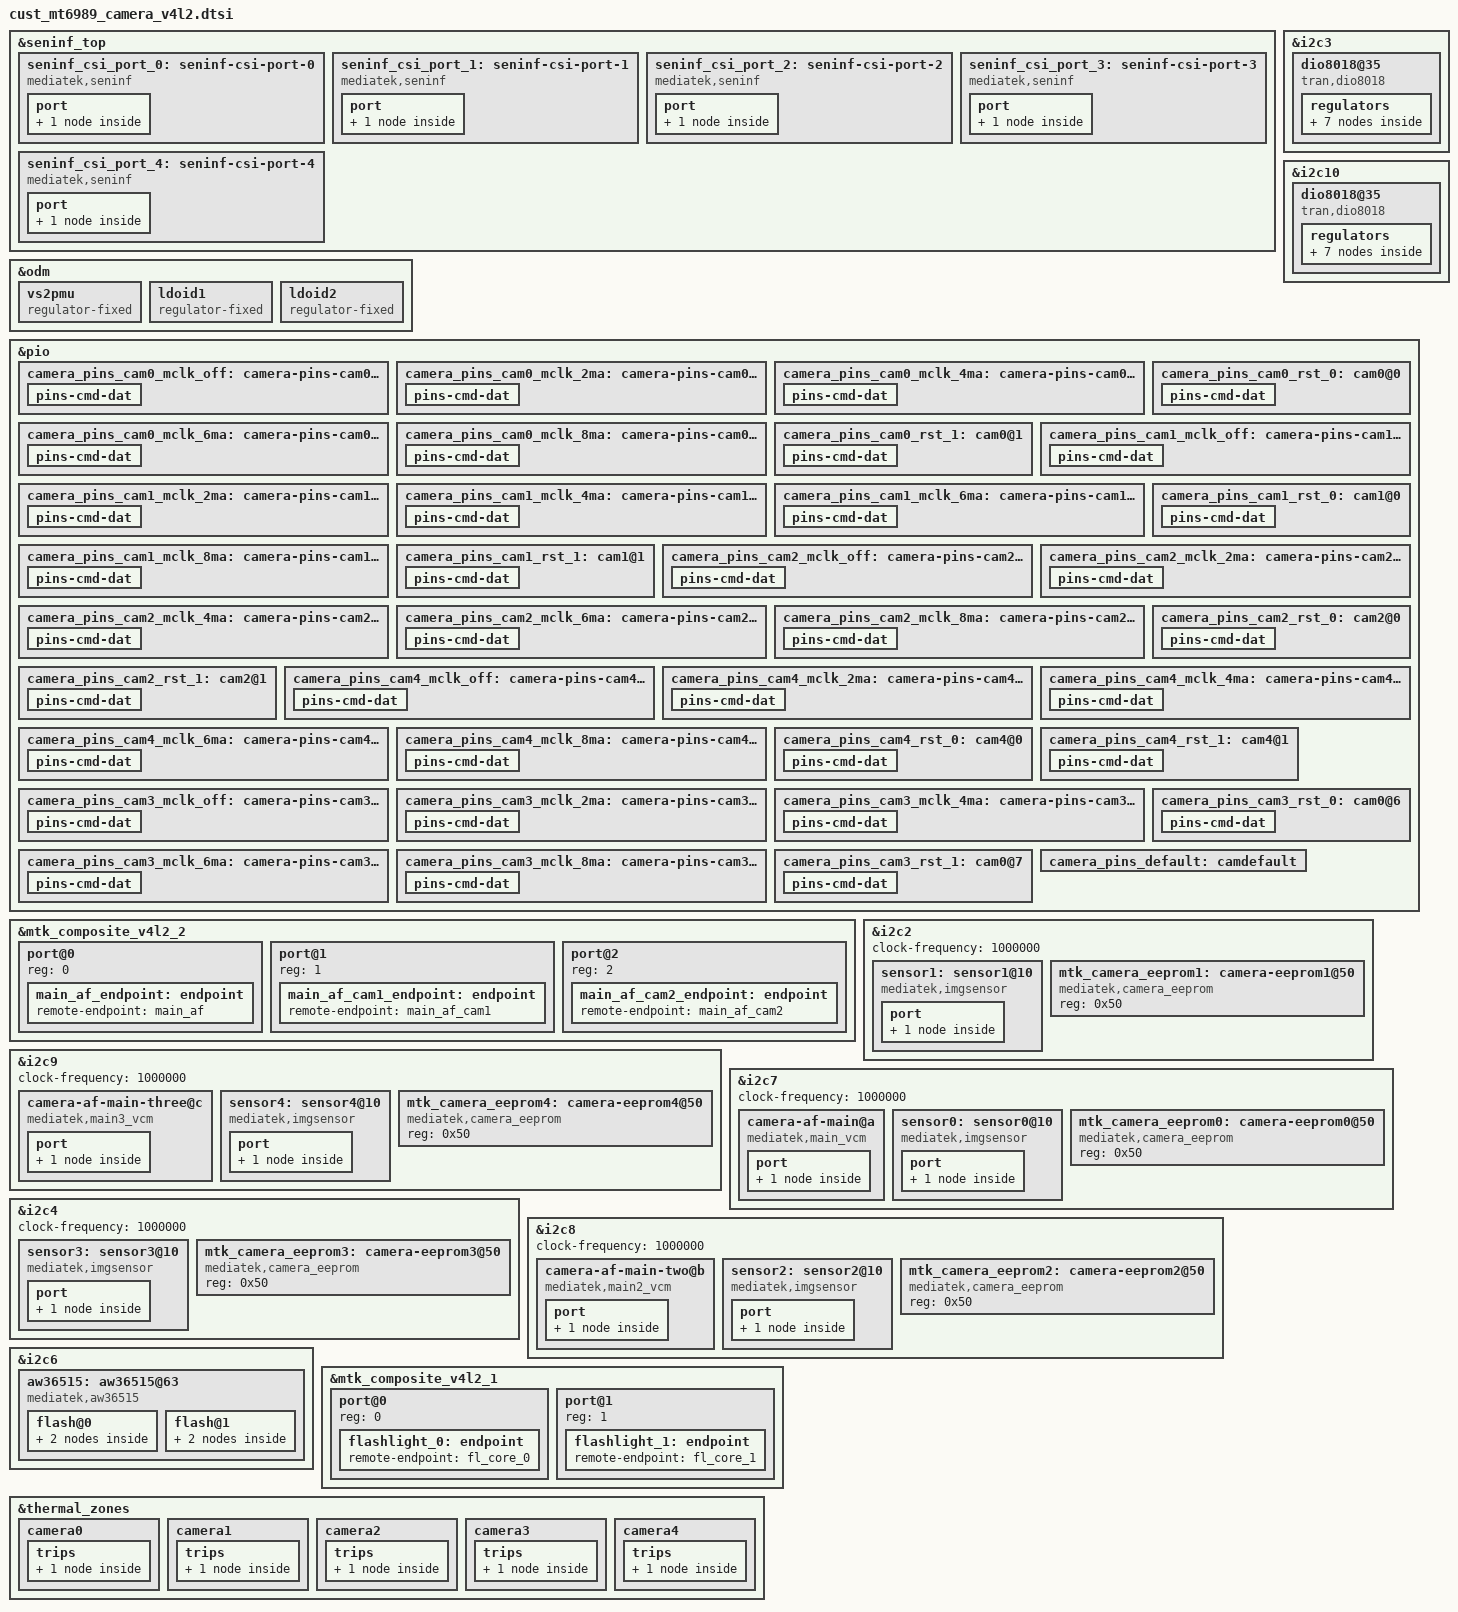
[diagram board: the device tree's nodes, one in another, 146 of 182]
// SPDX-License-Identifier: GPL-2.0
/* Copyright (c) 2023 MediaTek Inc. */
#include <dt-bindings/clock/mt6989-clk.h>

&seninf_top {
		seninf_csi_port_0: seninf-csi-port-0 {
			compatible = "mediatek,seninf";
			csi-port = "0";

			nvmem-cells = <&csi_efuse0>;
			nvmem-cell-names = "rg_csi";

			port {
				seninf_csi_port_0_in: endpoint {
					remote-endpoint = <&sensor4_out>;
				};
			};
		};

		seninf_csi_port_1: seninf-csi-port-1 {
			compatible = "mediatek,seninf";
			csi-port = "1";

			nvmem-cells = <&csi_efuse1>;
			nvmem-cell-names = "rg_csi";

			port {
				seninf_csi_port_1_in: endpoint {
					remote-endpoint = <&sensor2_out>;
				};
			};
		};

		seninf_csi_port_2: seninf-csi-port-2 {
			compatible = "mediatek,seninf";
			csi-port = "2";

			nvmem-cells = <&csi_efuse2>;
			nvmem-cell-names = "rg_csi";

			port {
				seninf_csi_port_2_in: endpoint {
					remote-endpoint = <&sensor1_out>;
				};
			};
		};
		seninf_csi_port_3: seninf-csi-port-3 {
			compatible = "mediatek,seninf";
			csi-port = "3";

			nvmem-cells = <&csi_efuse3>;
			nvmem-cell-names = "rg_csi";

			port {
				seninf_csi_port_3_in: endpoint {
					remote-endpoint = <&sensor0_out>;
				};
			};
		};
		seninf_csi_port_4: seninf-csi-port-4 {
			compatible = "mediatek,seninf";
			csi-port = "4";

			nvmem-cells = <&csi_efuse4>;
			nvmem-cell-names = "rg_csi";

			port {
				seninf_csi_port_4_in: endpoint {
					remote-endpoint = <&sensor3_out>;
				};
			};
		};
};

&i2c3 {
	#address-cells = <1>;
	#size-cells = <0>;

	dio8018@35 {
	    compatible = "tran,dio8018";
	    reg = <0x35>;
	    VINA-supply = <&vs2pmu>;
	    regulators {
	        DIO8018LDO13:DIO8018LDO13 {
	            regulator-name = "DIO8018LDO13";
	            regulator-min-microvolt = <800000>;
	            regulator-max-microvolt = <1800000>;
	        };
	        DIO8018LDO23:DIO8018LDO23 {
	            regulator-name = "DIO8018LDO23";
	            regulator-min-microvolt = <800000>;
	            regulator-max-microvolt = <1800000>;
	        };
	        DIO8018LDO33:DIO8018LDO33 {
	            regulator-name = "DIO8018LDO33";
	            regulator-min-microvolt = <1500000>;
	            regulator-max-microvolt = <3900000>;
	        };
	        DIO8018LDO43:DIO8018LDO43 {
	            regulator-name = "DIO8018LDO43";
	            regulator-min-microvolt = <1500000>;
	            regulator-max-microvolt = <3900000>;
	        };
	        DIO8018LDO53:DIO8018LDO53 {
	            regulator-name = "DIO8018LDO53";
	            regulator-min-microvolt = <3300000>;
	            regulator-max-microvolt = <3300000>;
	        };
	        DIO8018LDO63:DIO8018LDO63 {
	            regulator-name = "DIO8018LDO63";
	            regulator-min-microvolt = <1500000>;
	            regulator-max-microvolt = <3900000>;
	        };
	        DIO8018LDO73:DIO8018LDO73 {
	            regulator-name = "DIO8018LDO73";
	            regulator-min-microvolt = <1500000>;
	            regulator-max-microvolt = <3900000>;
	        };
	    };
	};
};

&i2c10 {
	#address-cells = <1>;
	#size-cells = <0>;

	dio8018@35 {
	    compatible = "tran,dio8018";
	    reg = <0x35>;
	    VINA-supply = <&vs2pmu>;
	    regulators {
	        DIO8018LDO110:DIO8018LDO110 {
	            regulator-name = "DIO8018LDO110";
	            regulator-min-microvolt = <800000>;
	            regulator-max-microvolt = <1800000>;
	        };
	        DIO8018LDO210:DIO8018LDO210 {
	            regulator-name = "DIO8018LDO210";
	            regulator-min-microvolt = <800000>;
	            regulator-max-microvolt = <1800000>;
	        };
	        DIO8018LDO310:DIO8018LDO310 {
	            regulator-name = "DIO8018LDO310";
	            regulator-min-microvolt = <1500000>;
	            regulator-max-microvolt = <3900000>;
	        };
	        DIO8018LDO410:DIO8018LDO410 {
	            regulator-name = "DIO8018LDO410";
	            regulator-min-microvolt = <1500000>;
	            regulator-max-microvolt = <3900000>;
	        };
	        DIO8018LDO510:DIO8018LDO510 {
	            regulator-name = "DIO8018LDO510";
	            regulator-min-microvolt = <3300000>;
	            regulator-max-microvolt = <3300000>;
	        };
	        DIO8018LDO610:DIO8018LDO610 {
	            regulator-name = "DIO8018LDO610";
	            regulator-min-microvolt = <2804000>;
	            regulator-max-microvolt = <2804000>;
	        };
	        DIO8018LDO710:DIO8018LDO710 {
	            regulator-name = "DIO8018LDO710";
	            regulator-min-microvolt = <1500000>;
	            regulator-max-microvolt = <3900000>;
	        };
	    };
	};
};

/* CAMERA GPIO fixed to regulator */
&odm {
	vs2pmu: vs2pmu {
		compatible = "regulator-fixed";
		regulator-name = "vs2pmu";
		regulator-min-microvolt = <1800000>;
		regulator-max-microvolt = <1800000>;
		gpio = <&pio 153 0x0>;
		enable-active-high;
		regulator-always-on;
		regulator-boot-on;
	};

	ldoid1: ldoid1 {
		compatible = "regulator-fixed";
		regulator-name = "ldoid1";
		regulator-min-microvolt = <1800000>;
		regulator-max-microvolt = <1800000>;
		gpio = <&pio 90 0x0>;
		enable-active-high;
		regulator-always-on;
		regulator-boot-on;
	};

	ldoid2: ldoid2 {
		compatible = "regulator-fixed";
		regulator-name = "ldoid2";
		regulator-min-microvolt = <1800000>;
		regulator-max-microvolt = <1800000>;
		gpio = <&pio 107 0x0>;
		enable-active-high;
		regulator-always-on;
		regulator-boot-on;
	};
};

/* CAMERA GPIO standardization */
&pio {
	camera_pins_cam0_mclk_off: camera-pins-cam0-mclk-off {
		pins-cmd-dat {
			pinmux = <PINMUX_GPIO124__FUNC_GPIO124>;
			drive-strength = <1>;
		};
	};
	camera_pins_cam0_mclk_2ma: camera-pins-cam0-mclk-2ma {
		pins-cmd-dat {
			pinmux = <PINMUX_GPIO124__FUNC_CMMCLK0>;
			drive-strength = <0>;
		};
	};
	camera_pins_cam0_mclk_4ma: camera-pins-cam0-mclk-4ma {
		pins-cmd-dat {
			pinmux = <PINMUX_GPIO124__FUNC_CMMCLK0>;
			drive-strength = <1>;
		};
	};
	camera_pins_cam0_mclk_6ma: camera-pins-cam0-mclk-6ma {
		pins-cmd-dat {
			pinmux = <PINMUX_GPIO124__FUNC_CMMCLK0>;
			drive-strength = <2>;
		};
	};
	camera_pins_cam0_mclk_8ma: camera-pins-cam0-mclk-8ma {
		pins-cmd-dat {
			pinmux = <PINMUX_GPIO124__FUNC_CMMCLK0>;
			drive-strength = <3>;
		};
	};
	camera_pins_cam0_rst_0: cam0@0 {
		pins-cmd-dat {
			pinmux = <PINMUX_GPIO126__FUNC_GPIO126>;                     //cam0 reset
			slew-rate = <1>;
			output-low;
		};
	};
	camera_pins_cam0_rst_1: cam0@1 {
		pins-cmd-dat {
			pinmux = <PINMUX_GPIO126__FUNC_GPIO126>;
			slew-rate = <1>;
			output-high;
		};
	};
	camera_pins_cam1_mclk_off: camera-pins-cam1-mclk-off {
		pins-cmd-dat {
			pinmux = <PINMUX_GPIO106__FUNC_GPIO106>;
			drive-strength = <1>;
		};
	};
	camera_pins_cam1_mclk_2ma: camera-pins-cam1-mclk-2ma {
		pins-cmd-dat {
			pinmux = <PINMUX_GPIO106__FUNC_CMMCLK4>;
			drive-strength = <0>;
		};
	};
	camera_pins_cam1_mclk_4ma: camera-pins-cam1-mclk-4ma {
		pins-cmd-dat {
			pinmux = <PINMUX_GPIO106__FUNC_CMMCLK4>;
			drive-strength = <1>;
		};
	};
	camera_pins_cam1_mclk_6ma: camera-pins-cam1-mclk-6ma {
		pins-cmd-dat {
			pinmux = <PINMUX_GPIO106__FUNC_CMMCLK4>;
			drive-strength = <2>;
		};
	};
	camera_pins_cam1_mclk_8ma: camera-pins-cam1-mclk-8ma {
		pins-cmd-dat {
			pinmux = <PINMUX_GPIO106__FUNC_CMMCLK4>;
			drive-strength = <3>;
		};
	};
	camera_pins_cam1_rst_0: cam1@0 {
		pins-cmd-dat {
			pinmux = <PINMUX_GPIO127__FUNC_GPIO127>;                    //reset cam1
			slew-rate = <1>;
			output-low;
		};
	};
	camera_pins_cam1_rst_1: cam1@1 {
		pins-cmd-dat {
			pinmux = <PINMUX_GPIO127__FUNC_GPIO127>;
			slew-rate = <1>;
			output-high;
		};
	};
	camera_pins_cam2_mclk_off: camera-pins-cam2-mclk-off {
		pins-cmd-dat {
			pinmux = <PINMUX_GPIO116__FUNC_GPIO116>;
			drive-strength = <1>;
		};
	};
	camera_pins_cam2_mclk_2ma: camera-pins-cam2-mclk-2ma {
		pins-cmd-dat {
			pinmux = <PINMUX_GPIO116__FUNC_CMMCLK2>;
			drive-strength = <0>;
		};
	};
	camera_pins_cam2_mclk_4ma: camera-pins-cam2-mclk-4ma {
		pins-cmd-dat {
			pinmux = <PINMUX_GPIO116__FUNC_CMMCLK2>;
			drive-strength = <1>;
		};
	};
	camera_pins_cam2_mclk_6ma: camera-pins-cam2-mclk-6ma {
		pins-cmd-dat {
			pinmux = <PINMUX_GPIO116__FUNC_CMMCLK2>;
			drive-strength = <2>;
		};
	};
	camera_pins_cam2_mclk_8ma: camera-pins-cam2-mclk-8ma {
		pins-cmd-dat {
			pinmux = <PINMUX_GPIO116__FUNC_CMMCLK2>;
			drive-strength = <3>;
		};
	};
	camera_pins_cam2_rst_0: cam2@0 {
		pins-cmd-dat {
			pinmux = <PINMUX_GPIO118__FUNC_GPIO118>;                    //cam2 reset
			slew-rate = <1>;
			output-low;
		};
	};
	camera_pins_cam2_rst_1: cam2@1 {
		pins-cmd-dat {
			pinmux = <PINMUX_GPIO118__FUNC_GPIO118>;
			slew-rate = <1>;
			output-high;
		};
	};

	camera_pins_cam4_mclk_off: camera-pins-cam4-mclk-off {
		pins-cmd-dat {
			pinmux = <PINMUX_GPIO117__FUNC_GPIO117>;
			drive-strength = <1>;
		};
	};
	camera_pins_cam4_mclk_2ma: camera-pins-cam4-mclk-2ma {
		pins-cmd-dat {
			pinmux = <PINMUX_GPIO117__FUNC_CMMCLK3>;
			drive-strength = <0>;
		};
	};
	camera_pins_cam4_mclk_4ma: camera-pins-cam4-mclk-4ma {
		pins-cmd-dat {
			pinmux = <PINMUX_GPIO117__FUNC_CMMCLK3>;
			drive-strength = <1>;
		};
	};
	camera_pins_cam4_mclk_6ma: camera-pins-cam4-mclk-6ma {
		pins-cmd-dat {
			pinmux = <PINMUX_GPIO117__FUNC_CMMCLK3>;
			drive-strength = <2>;
		};
	};
	camera_pins_cam4_mclk_8ma: camera-pins-cam4-mclk-8ma {
		pins-cmd-dat {
			pinmux = <PINMUX_GPIO117__FUNC_CMMCLK3>;
			drive-strength = <3>;
		};
	};
	camera_pins_cam4_rst_0: cam4@0 {
		pins-cmd-dat {
			pinmux = <PINMUX_GPIO119__FUNC_GPIO119>;                 //cam4 reset
			slew-rate = <1>;
			output-low;
		};
	};
	camera_pins_cam4_rst_1: cam4@1 {
		pins-cmd-dat {
			pinmux = <PINMUX_GPIO119__FUNC_GPIO119>;
			slew-rate = <1>;
			output-high;
		};
	};
	camera_pins_cam3_mclk_off: camera-pins-cam3-mclk-off {
		pins-cmd-dat {
			pinmux = <PINMUX_GPIO125__FUNC_GPIO125>;
			drive-strength = <1>;
		};
	};
	camera_pins_cam3_mclk_2ma: camera-pins-cam3-mclk-2ma {
		pins-cmd-dat {
			pinmux = <PINMUX_GPIO125__FUNC_CMMCLK1>;
			drive-strength = <0>;
		};
	};
	camera_pins_cam3_mclk_4ma: camera-pins-cam3-mclk-4ma {
		pins-cmd-dat {
			pinmux = <PINMUX_GPIO125__FUNC_CMMCLK1>;
			drive-strength = <1>;
		};
	};
	camera_pins_cam3_mclk_6ma: camera-pins-cam3-mclk-6ma {
		pins-cmd-dat {
			pinmux = <PINMUX_GPIO125__FUNC_CMMCLK1>;
			drive-strength = <2>;
		};
	};
	camera_pins_cam3_mclk_8ma: camera-pins-cam3-mclk-8ma {
		pins-cmd-dat {
			pinmux = <PINMUX_GPIO125__FUNC_CMMCLK1>;
			drive-strength = <3>;
		};
	};
	camera_pins_cam3_rst_0: cam0@6 {
		pins-cmd-dat {
			pinmux = <PINMUX_GPIO110__FUNC_GPIO110>;
			slew-rate = <1>;
			output-low;
		};
	};
	camera_pins_cam3_rst_1: cam0@7 {
		pins-cmd-dat {
			pinmux = <PINMUX_GPIO110__FUNC_GPIO110>;
			slew-rate = <1>;
			output-high;
		};
	};
	camera_pins_default: camdefault {
	};
};
/* CAMERA GPIO end */

&mtk_composite_v4l2_2 {
	#address-cells = <1>;
	#size-cells = <0>;
	port@0 {
		reg = <0>;
		main_af_endpoint: endpoint {
			remote-endpoint = <&main_af>;
		};
	};
	port@1 {
		reg = <1>;
		main_af_cam1_endpoint: endpoint {
			remote-endpoint = <&main_af_cam1>;
		};
	};
	port@2 {
		reg = <2>;
		main_af_cam2_endpoint: endpoint {
			remote-endpoint = <&main_af_cam2>;
		};
	};
};

&i2c2 {
	status = "okay";
	clock-frequency = <1000000>;

	sensor1: sensor1@10 {
		compatible = "mediatek,imgsensor";
		sensor-names = "hi3231qsub1_mipi_raw";
		reg = <0x10>;

		#thermal-sensor-cells = <0>;
		sensor-matecodes = "hi3231qsub1_17201878";
		pinctrl-names = "mclk_off",
				"mclk_2mA",
				"mclk_4mA",
				"mclk_6mA",
				"mclk_8mA",
				"rst_low",
				"rst_high";
		pinctrl-0 = <&camera_pins_cam1_mclk_off>;
		pinctrl-1 = <&camera_pins_cam1_mclk_2ma>;
		pinctrl-2 = <&camera_pins_cam1_mclk_4ma>;
		pinctrl-3 = <&camera_pins_cam1_mclk_6ma>;
		pinctrl-4 = <&camera_pins_cam1_mclk_8ma>;
		pinctrl-5 = <&camera_pins_cam1_rst_0>;
		pinctrl-6 = <&camera_pins_cam1_rst_1>;

		avdd-supply = <&DIO8018LDO43>;
		dvdd-supply = <&DIO8018LDO23>;
		dovdd-supply = <&mt6373_vrfio18_aif>;

		clocks = <&topckgen_clk CLK_TOP_UNIVPLL2_192M_D32>,
			<&topckgen_clk CLK_TOP_UNIVPLL2_192M_D16>,
			<&topckgen_clk CLK_TOP_F26M_CK_D2>,
			<&topckgen_clk CLK_TOP_UNIVPLL2_192M_D10>,
			<&topckgen_clk CLK_TOP_UNIVPLL2_192M_D8>,
			<&topckgen_clk CLK_TOP_UNIVPLL2_D6_D16>,
			<&topckgen_clk CLK_TOP_UNIVPLL2_D6_D8>,
			<&topckgen_clk CLK_TOP_CAMTG4_SEL>;
		clock-names = "6", "12", "13", "19.2", "24", "26", "52", "mclk";

		status = "okay";
		port {
			sensor1_out: endpoint {
				remote-endpoint = <&seninf_csi_port_2_in>;
			};
		};
	};

	mtk_camera_eeprom1:camera-eeprom1@50 {
		compatible = "mediatek,camera_eeprom";
		reg = <0x50>;
		status = "okay";
	};
};

&i2c9 {
	status = "okay";
	clock-frequency = <1000000>;

	camera-af-main-three@c {
		compatible = "mediatek,main3_vcm";
		reg = <0x0b>;
		vin-supply = <&DIO8018LDO610>;
		port {
			main_af_cam2: endpoint {
				remote-endpoint = <&main_af_cam2_endpoint>;
			};
		};
	};

	sensor4: sensor4@10 {
		compatible = "mediatek,imgsensor";
		sensor-names = "hi5022qwide_mipi_raw";
		reg = <0x10>;

		#thermal-sensor-cells = <0>;
		sensor-type = "main3";
		sensor-matecodes = "hi5022qwide_17201862";
		pinctrl-names = "mclk_off",
				"mclk_2mA",
				"mclk_4mA",
				"mclk_6mA",
				"mclk_8mA",
				"rst_low",
				"rst_high";
		pinctrl-0 = <&camera_pins_cam4_mclk_off>;
		pinctrl-1 = <&camera_pins_cam4_mclk_2ma>;
		pinctrl-2 = <&camera_pins_cam4_mclk_4ma>;
		pinctrl-3 = <&camera_pins_cam4_mclk_6ma>;
		pinctrl-4 = <&camera_pins_cam4_mclk_8ma>;
		pinctrl-5 = <&camera_pins_cam4_rst_0>;
		pinctrl-6 = <&camera_pins_cam4_rst_1>;

		avdd-supply = <&DIO8018LDO410>;
		dvdd-supply = <&DIO8018LDO210>;
		dovdd-supply = <&mt6373_vrfio18_aif>;

		clocks = <&topckgen_clk CLK_TOP_UNIVPLL2_192M_D32>,
			<&topckgen_clk CLK_TOP_UNIVPLL2_192M_D16>,
			<&topckgen_clk CLK_TOP_F26M_CK_D2>,
			<&topckgen_clk CLK_TOP_UNIVPLL2_192M_D10>,
			<&topckgen_clk CLK_TOP_UNIVPLL2_192M_D8>,
			<&topckgen_clk CLK_TOP_UNIVPLL2_D6_D16>,
			<&topckgen_clk CLK_TOP_UNIVPLL2_D6_D8>,
			<&topckgen_clk CLK_TOP_CAMTG3_SEL>;
		clock-names = "6", "12", "13", "19.2", "24", "26", "52", "mclk";

		status = "okay";
		port {
			sensor4_out: endpoint {
				remote-endpoint = <&seninf_csi_port_0_in>;
			};
		};
	};

	mtk_camera_eeprom4:camera-eeprom4@50 {
		compatible = "mediatek,camera_eeprom";
		reg = <0x50>;
		status = "okay";
	};
};

&i2c7 {
	status = "okay";
	clock-frequency = <1000000>;

	camera-af-main@a {
		compatible = "mediatek,main_vcm";
		reg = <0x0a>;
		vin-supply = <&DIO8018LDO53>;
		port {
			main_af: endpoint {
				remote-endpoint = <&main_af_endpoint>;
			};
		};
	};

	sensor0: sensor0@10 {
		compatible = "mediatek,imgsensor";
		sensor-names = "imx890_mipi_raw";
		reg = <0x10>;

		#thermal-sensor-cells = <0>;
		sensor-matecodes = "imx890_17201871";
		pinctrl-names = "mclk_off",
				"mclk_2mA",
				"mclk_4mA",
				"mclk_6mA",
				"mclk_8mA",
				"rst_low",
				"rst_high";
		pinctrl-0 = <&camera_pins_cam0_mclk_off>;
		pinctrl-1 = <&camera_pins_cam0_mclk_2ma>;
		pinctrl-2 = <&camera_pins_cam0_mclk_4ma>;
		pinctrl-3 = <&camera_pins_cam0_mclk_6ma>;
		pinctrl-4 = <&camera_pins_cam0_mclk_8ma>;
		pinctrl-5 = <&camera_pins_cam0_rst_0>;
		pinctrl-6 = <&camera_pins_cam0_rst_1>;

		avdd-supply = <&DIO8018LDO33>;
		avdd1-supply = <&DIO8018LDO63>;
		dvdd-supply = <&DIO8018LDO13>;
		dovdd-supply = <&mt6373_vrfio18_aif>;

		clocks = <&topckgen_clk CLK_TOP_UNIVPLL_192M_D32>,
			<&topckgen_clk CLK_TOP_UNIVPLL_192M_D16>,
			<&topckgen_clk CLK_TOP_F26M_CK_D2>,
			<&topckgen_clk CLK_TOP_UNIVPLL_192M_D10>,
			<&topckgen_clk CLK_TOP_UNIVPLL_192M_D8>,
			<&topckgen_clk CLK_TOP_UNIVPLL_D6_D16>,
			<&topckgen_clk CLK_TOP_UNIVPLL_D6_D8>,
			<&vlp_cksys_clk CLK_VLP_CK_CAMTG0_SEL>;
		clock-names = "6", "12", "13", "19.2", "24", "26", "52", "mclk";

		status = "okay";
		port {
			sensor0_out: endpoint {
				remote-endpoint = <&seninf_csi_port_3_in>;
			};
		};
	};

	mtk_camera_eeprom0:camera-eeprom0@50 {
		compatible = "mediatek,camera_eeprom";
		reg = <0x50>;
		status = "okay";
	};
};

&i2c4 {
	status = "okay";
	clock-frequency = <1000000>;

	sensor3: sensor3@10 {
		compatible = "mediatek,imgsensor";
		sensor-names = "hi3231qsub2_mipi_raw";
		reg = <0x10>;

		#thermal-sensor-cells = <0>;
		sensor-type = "sub2";
		sensor-matecodes = "hi3231qsub2_17201879";
		sensor-board = "aw95016";
		pinctrl-names = "mclk_off",
				"mclk_2mA",
				"mclk_4mA",
				"mclk_6mA",
				"mclk_8mA",
				"rst_low",
				"rst_high";
		pinctrl-0 = <&camera_pins_cam3_mclk_off>;
		pinctrl-1 = <&camera_pins_cam3_mclk_2ma>;
		pinctrl-2 = <&camera_pins_cam3_mclk_4ma>;
		pinctrl-3 = <&camera_pins_cam3_mclk_6ma>;
		pinctrl-4 = <&camera_pins_cam3_mclk_8ma>;
		pinctrl-5 = <&camera_pins_cam3_rst_0>;
		pinctrl-6 = <&camera_pins_cam3_rst_1>;

		avdd-supply = <&mt6373_vcn18io>;
		dvdd-supply = <&mt6373_vcn18io>;
		dovdd-supply = <&mt6373_vcn18io>;

		clocks = <&topckgen_clk CLK_TOP_UNIVPLL2_192M_D32>,
			<&topckgen_clk CLK_TOP_UNIVPLL2_192M_D16>,
			<&topckgen_clk CLK_TOP_F26M_CK_D2>,
			<&topckgen_clk CLK_TOP_UNIVPLL2_192M_D10>,
			<&topckgen_clk CLK_TOP_UNIVPLL2_192M_D8>,
			<&topckgen_clk CLK_TOP_UNIVPLL2_D6_D16>,
			<&topckgen_clk CLK_TOP_UNIVPLL2_D6_D8>,
			<&topckgen_clk CLK_TOP_CAMTG1_SEL>;
		clock-names = "6", "12", "13", "19.2", "24", "26", "52", "mclk";

		status = "okay";
		port {
			sensor3_out: endpoint {
				remote-endpoint = <&seninf_csi_port_4_in>;
			};
		};
	};

	mtk_camera_eeprom3:camera-eeprom3@50 {
		compatible = "mediatek,camera_eeprom";
		reg = <0x50>;
		status = "okay";
	};
};

&i2c8 {
	status = "okay";
	clock-frequency = <1000000>;

	camera-af-main-two@b {
		compatible = "mediatek,main2_vcm";
		reg = <0x0d>;
		vin-supply = <&DIO8018LDO510>;
		port {
			main_af_cam1: endpoint {
				remote-endpoint = <&main_af_cam1_endpoint>;
			};
		};
	};

	sensor2: sensor2@10 {
		compatible = "mediatek,imgsensor";
		sensor-names = "s5kjn1tele_mipi_raw";
		reg = <0x10>;

		#thermal-sensor-cells = <0>;
		sensor-matecodes = "s5kjn1tele_17201860";
		pinctrl-names = "mclk_off",
				"mclk_2mA",
				"mclk_4mA",
				"mclk_6mA",
				"mclk_8mA",
				"rst_low",
				"rst_high";
		pinctrl-0 = <&camera_pins_cam2_mclk_off>;
		pinctrl-1 = <&camera_pins_cam2_mclk_2ma>;
		pinctrl-2 = <&camera_pins_cam2_mclk_4ma>;
		pinctrl-3 = <&camera_pins_cam2_mclk_6ma>;
		pinctrl-4 = <&camera_pins_cam2_mclk_8ma>;
		pinctrl-5 = <&camera_pins_cam2_rst_0>;
		pinctrl-6 = <&camera_pins_cam2_rst_1>;

		avdd-supply = <&DIO8018LDO310>;
		dvdd-supply = <&DIO8018LDO110>;
		dovdd-supply = <&mt6373_vrfio18_aif>;

		clocks = <&topckgen_clk CLK_TOP_UNIVPLL2_192M_D32>,
			<&topckgen_clk CLK_TOP_UNIVPLL2_192M_D16>,
			<&topckgen_clk CLK_TOP_F26M_CK_D2>,
			<&topckgen_clk CLK_TOP_UNIVPLL2_192M_D10>,
			<&topckgen_clk CLK_TOP_UNIVPLL2_192M_D8>,
			<&topckgen_clk CLK_TOP_UNIVPLL2_D6_D16>,
			<&topckgen_clk CLK_TOP_UNIVPLL2_D6_D8>,
			<&topckgen_clk CLK_TOP_CAMTG2_SEL>;
		clock-names = "6", "12", "13", "19.2", "24", "26", "52", "mclk";

		status = "okay";
		port {
			sensor2_out: endpoint {
				remote-endpoint = <&seninf_csi_port_1_in>;
			};
		};
	};

	mtk_camera_eeprom2:camera-eeprom2@50 {
		compatible = "mediatek,camera_eeprom";
		reg = <0x50>;
		status = "okay";
	};
};

&i2c6 {
	#address-cells = <1>;
	#size-cells = <0>;
	aw36515:aw36515@63 {
		compatible = "mediatek,aw36515";
		#address-cells = <1>;
		#size-cells = <0>;
		reg = <0x63>;
		flashledno = <1>;
		#cooling-cells = <2>;
/*		pinctrl-names = "default", "hwen-high", "hwen-low";
		pinctrl-0 = <&aw36515_pins_default>;
		pinctrl-1 = <&aw36515_pins_hwen_high>;
		pinctrl-2 = <&aw36515_pins_hwen_low>;*/
		status = "okay";
		flash@0{
			reg = <1>;
			type = <1>;
			ct = <0>;
			part = <0>;
			port {
				fl_core_0: endpoint {
					remote-endpoint = <&flashlight_0>;
				};
			};
		};
		flash@1{
			reg = <0>;
			type = <0>;
			ct = <0>;
			part = <0>;
			port {
				fl_core_1: endpoint {
					remote-endpoint = <&flashlight_1>;
				};
			};
		};
	};
};
/*
&pio {
	aw36515_pins_default: default {
	};

	aw36515_pins_hwen_high: hwen-high {
		pins-cmd-dat {
			pinmux = <PINMUX_GPIO17__FUNC_GPIO17>;
			slew-rate = <1>;
			output-high;
		};
	};

	aw36515_pins_hwen_low: hwen-low {
		pins-cmd-dat {
			pinmux = <PINMUX_GPIO17__FUNC_GPIO17>;
			slew-rate = <1>;
			output-low;
		};
	};
};
*/
&mtk_composite_v4l2_1 {
	#address-cells = <1>;
	#size-cells = <0>;
	port@0 {
		reg = <0>;
		flashlight_0: endpoint {
			remote-endpoint = <&fl_core_0>;
		};
	};
	port@1 {
		reg = <1>;
		flashlight_1: endpoint {
			remote-endpoint = <&fl_core_1>;
		};
	};
};


&thermal_zones {
	camera0: camera0 {
		polling-delay = <0>; /* milliseconds */
		polling-delay-passive = <0>; /* milliseconds */
		thermal-sensors = <&sensor0>;
		trips {
			camera0_crit: camera0-crit {
				temperature = <120000>;
				hysteresis = <2000>;
				type = "passive";
			};
		};
	};
	camera1: camera1 {
		polling-delay = <0>; /* milliseconds */
		polling-delay-passive = <0>; /* milliseconds */
		thermal-sensors = <&sensor1>;
		trips {
			camera1_crit: camera1-crit {
				temperature = <120000>;
				hysteresis = <2000>;
				type = "passive";
			};
		};
	};
	camera2: camera2 {
		polling-delay = <0>; /* milliseconds */
		polling-delay-passive = <0>; /* milliseconds */
		thermal-sensors = <&sensor2>;
		trips {
			camera2_crit: camera2-crit {
				temperature = <120000>;
				hysteresis = <2000>;
				type = "passive";
			};
		};
	};
	camera3: camera3 {
		polling-delay = <0>; /* milliseconds */
		polling-delay-passive = <0>; /* milliseconds */
		thermal-sensors = <&sensor3>;
		trips {
			camera3_crit: camera3-crit {
				temperature = <120000>;
				hysteresis = <2000>;
				type = "passive";
			};
		};
	};
	camera4: camera4 {
		polling-delay = <0>; /* milliseconds */
		polling-delay-passive = <0>; /* milliseconds */
		thermal-sensors = <&sensor4>;
		trips {
			camera4_crit: camera4-crit {
				temperature = <120000>;
				hysteresis = <2000>;
				type = "passive";
			};
		};
	};
};
